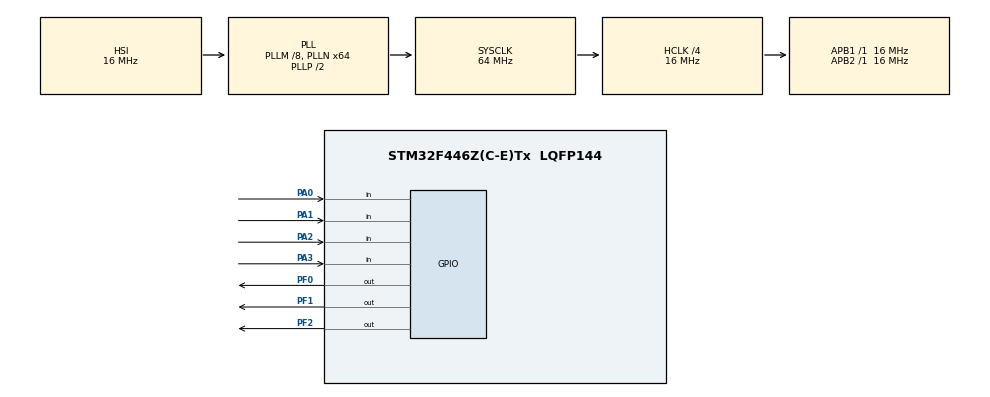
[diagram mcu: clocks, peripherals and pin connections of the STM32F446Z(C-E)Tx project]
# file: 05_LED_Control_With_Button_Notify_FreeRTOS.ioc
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FREERTOS.Tasks01=defaultTask,24,128,StartDefaultTask,Default,NULL,Dynamic,NULL,NULL;myTask02,8,128,StartTask02,Default,NULL,Dynamic,NULL,NULL;myTask03,8,128,StartTask03,Default,NULL,Dynamic,NULL,NULL
Mcu.Family=STM32F4
Mcu.Name=STM32F446Z(C-E)Tx
Mcu.Package=LQFP144
NVIC.PriorityGroup=NVIC_PRIORITYGROUP_4
PA0-WKUP.Signal=GPIO_Input
PA1.Signal=GPIO_Input
PA13.Mode=Serial_Wire
PA13.Signal=SYS_JTMS-SWDIO
PA14.Mode=Serial_Wire
PA14.Signal=SYS_JTCK-SWCLK
PA2.Signal=GPIO_Input
PA3.Signal=GPIO_Input
PF0.Signal=GPIO_Output
PF1.Signal=GPIO_Output
PF2.Signal=GPIO_Output
PH0-OSC_IN.Mode=HSE-External-Oscillator
PH0-OSC_IN.Signal=RCC_OSC_IN
PH1-OSC_OUT.Mode=HSE-External-Oscillator
PH1-OSC_OUT.Signal=RCC_OSC_OUT
ProjectManager.HeapSize=0x200
ProjectManager.StackSize=0x400
ProjectManager.TargetToolchain=STM32CubeIDE
RCC.AHBCLKDivider=RCC_SYSCLK_DIV4
RCC.AHBFreq_Value=16000000
RCC.APB1Freq_Value=16000000
RCC.APB1TimFreq_Value=16000000
RCC.APB2Freq_Value=16000000
RCC.APB2TimFreq_Value=16000000
RCC.CortexFreq_Value=16000000
RCC.HCLKFreq_Value=16000000
RCC.HSE_VALUE=8000000
RCC.PLLM=8
RCC.PLLN=64
RCC.SYSCLKFreq_VALUE=64000000
RCC.SYSCLKSource=RCC_SYSCLKSOURCE_PLLCLK
RCC.USBFreq_Value=64000000
RCC.VCOOutputFreq_Value=128000000
VP_FREERTOS_VS_CMSIS_V2.Mode=CMSIS_V2
board=custom

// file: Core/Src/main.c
/* USER CODE BEGIN Header */
/**
  ******************************************************************************
  * @file           : main.c
  * @brief          : Main program body
  ******************************************************************************
  * @attention
  *
  * Copyright (c) 2024 STMicroelectronics.
  * All rights reserved.
  *
  * This software is licensed under terms that can be found in the LICENSE file
  * in the root directory of this software component.
  * If no LICENSE file comes with this software, it is provided AS-IS.
  *
  ******************************************************************************
  */
/* USER CODE END Header */
#include "main.h"
#include "cmsis_os.h"

/* Definitions for defaultTask */
osThreadId_t defaultTaskHandle;
const osThreadAttr_t defaultTask_attributes = {
  .name = "defaultTask",
  .stack_size = 128 * 4,
  .priority = (osPriority_t) osPriorityNormal,
};
/* Definitions for myTask02 */
osThreadId_t myTask02Handle;
const osThreadAttr_t myTask02_attributes = {
  .name = "myTask02",
  .stack_size = 128 * 4,
  .priority = (osPriority_t) osPriorityLow,
};
/* Definitions for myTask03 */
osThreadId_t myTask03Handle;
const osThreadAttr_t myTask03_attributes = {
  .name = "myTask03",
  .stack_size = 128 * 4,
  .priority = (osPriority_t) osPriorityLow,
};
/* USER CODE BEGIN PV */
uint8_t buttonCount = 0;
/* USER CODE END PV */

void SystemClock_Config(void);
static void MX_GPIO_Init(void);
void Read_Gpıo(void *argument);
void Led_flash(void *argument);
void StartTask03(void *argument);

/* USER CODE BEGIN PFP */
void delay_FreeRTOS(uint32_t delayMS);
/* USER CODE END PFP */

int main(void)
{

  /* MCU Configuration--------------------------------------------------------*/

  /* Reset of all peripherals, Initializes the Flash interface and the Systick. */
  HAL_Init();

  /* Configure the system clock */
  SystemClock_Config();

  /* Initialize all configured peripherals */
  MX_GPIO_Init();

  /* Init scheduler */
  osKernelInitialize();

  /* Create the thread(s) */
  /* creation of defaultTask */
  defaultTaskHandle = osThreadNew(Read_Gpıo, NULL, &defaultTask_attributes);

  /* creation of myTask02 */
  myTask02Handle = osThreadNew(Led_flash, NULL, &myTask02_attributes);

  /* creation of myTask03 */
  myTask03Handle = osThreadNew(StartTask03, NULL, &myTask03_attributes);

  /* Start scheduler */
  osKernelStart();

  /* We should never get here as control is now taken by the scheduler */
  /* Infinite loop */
  while (1)
  {

  }
}

void SystemClock_Config(void)
{
  RCC_OscInitTypeDef RCC_OscInitStruct = {0};
  RCC_ClkInitTypeDef RCC_ClkInitStruct = {0};

  /** Configure the main internal regulator output voltage
  */
  __HAL_RCC_PWR_CLK_ENABLE();
  __HAL_PWR_VOLTAGESCALING_CONFIG(PWR_REGULATOR_VOLTAGE_SCALE3);

  /** Initializes the RCC Oscillators according to the specified parameters
  * in the RCC_OscInitTypeDef structure.
  */
  RCC_OscInitStruct.OscillatorType = RCC_OSCILLATORTYPE_HSI;
  RCC_OscInitStruct.HSIState = RCC_HSI_ON;
  RCC_OscInitStruct.HSICalibrationValue = RCC_HSICALIBRATION_DEFAULT;
  RCC_OscInitStruct.PLL.PLLState = RCC_PLL_ON;
  RCC_OscInitStruct.PLL.PLLSource = RCC_PLLSOURCE_HSI;
  RCC_OscInitStruct.PLL.PLLM = 8;
  RCC_OscInitStruct.PLL.PLLN = 64;
  RCC_OscInitStruct.PLL.PLLP = RCC_PLLP_DIV2;
  RCC_OscInitStruct.PLL.PLLQ = 2;
  RCC_OscInitStruct.PLL.PLLR = 2;
  if (HAL_RCC_OscConfig(&RCC_OscInitStruct) != HAL_OK)
  {
    Error_Handler();
  }

  /** Initializes the CPU, AHB and APB buses clocks
  */
  RCC_ClkInitStruct.ClockType = RCC_CLOCKTYPE_HCLK|RCC_CLOCKTYPE_SYSCLK
                              |RCC_CLOCKTYPE_PCLK1|RCC_CLOCKTYPE_PCLK2;
  RCC_ClkInitStruct.SYSCLKSource = RCC_SYSCLKSOURCE_PLLCLK;
  RCC_ClkInitStruct.AHBCLKDivider = RCC_SYSCLK_DIV4;
  RCC_ClkInitStruct.APB1CLKDivider = RCC_HCLK_DIV1;
  RCC_ClkInitStruct.APB2CLKDivider = RCC_HCLK_DIV1;

  if (HAL_RCC_ClockConfig(&RCC_ClkInitStruct, FLASH_LATENCY_0) != HAL_OK)
  {
    Error_Handler();
  }
}

static void MX_GPIO_Init(void)
{
  GPIO_InitTypeDef GPIO_InitStruct = {0};

  /* GPIO Ports Clock Enable */
  __HAL_RCC_GPIOF_CLK_ENABLE();
  __HAL_RCC_GPIOH_CLK_ENABLE();
  __HAL_RCC_GPIOA_CLK_ENABLE();

  /*Configure GPIO pin Output Level */
  HAL_GPIO_WritePin(GPIOF, GPIO_PIN_0|GPIO_PIN_1|GPIO_PIN_2, GPIO_PIN_RESET);

  /*Configure GPIO pins : PF0 PF1 PF2 */
  GPIO_InitStruct.Pin = GPIO_PIN_0|GPIO_PIN_1|GPIO_PIN_2;
  GPIO_InitStruct.Mode = GPIO_MODE_OUTPUT_PP;
  GPIO_InitStruct.Pull = GPIO_NOPULL;
  GPIO_InitStruct.Speed = GPIO_SPEED_FREQ_LOW;
  HAL_GPIO_Init(GPIOF, &GPIO_InitStruct);

  /*Configure GPIO pins : PA0 PA1 PA2 PA3 */
  GPIO_InitStruct.Pin = GPIO_PIN_0|GPIO_PIN_1|GPIO_PIN_2|GPIO_PIN_3;
  GPIO_InitStruct.Mode = GPIO_MODE_INPUT;
  GPIO_InitStruct.Pull = GPIO_NOPULL;
  HAL_GPIO_Init(GPIOA, &GPIO_InitStruct);

}

/* USER CODE BEGIN 4 */
void delay_FreeRTOS(uint32_t delayMS)
{
	uint32_t currentTick = xTaskGetTickCount();
	uint32_t delayTick = pdMS_TO_TICKS(delayMS); //delayMS * configTICK_RATE_HZ / 1000;(HAzır fonk kulanıldı) //FREERTOSConfig.h da RATE değeri 1000

	while(xTaskGetTickCount() < (currentTick + delayTick));
}
/* USER CODE END 4 */

void Read_Gpıo(void *argument)
{
  /* USER CODE BEGIN 5 */
  /* Infinite loop */
  for(;;)
  {
	  if(HAL_GPIO_ReadPin(GPIOA, GPIO_PIN_1) ==  GPIO_PIN_SET)
	  {
		  delay_FreeRTOS(100); //butona basınca arg oluşuyor önlemek için yaptık
		  xTaskNotify(myTask02Handle,0x00,eIncrement);
	  }
    osDelay(1);
  }
  /* USER CODE END 5 */
}

void Led_flash(void *argument)
{
  /* USER CODE BEGIN StartTask02 */
  /* Infinite loop */
  for(;;)
  {
	  uint32_t pulNotificationValue = 0;
	  if(xTaskNotifyWait(0,0,&pulNotificationValue,portMAX_DELAY) == pdTRUE)
	  {
		  HAL_GPIO_TogglePin(GPIOF, GPIO_PIN_0 | GPIO_PIN_1 | GPIO_PIN_2);
		  buttonCount = pulNotificationValue; // çünkü eIncrement yaptık bildirim sayısı kaç defa saydığıdır aslında
	  }

    osDelay(1);
  }
  /* USER CODE END StartTask02 */
}

void StartTask03(void *argument)
{
  for(;;)
  {
    osDelay(1);
  }
}

void Error_Handler(void)
{
  __disable_irq();
  while (1)
  {
  }
}
